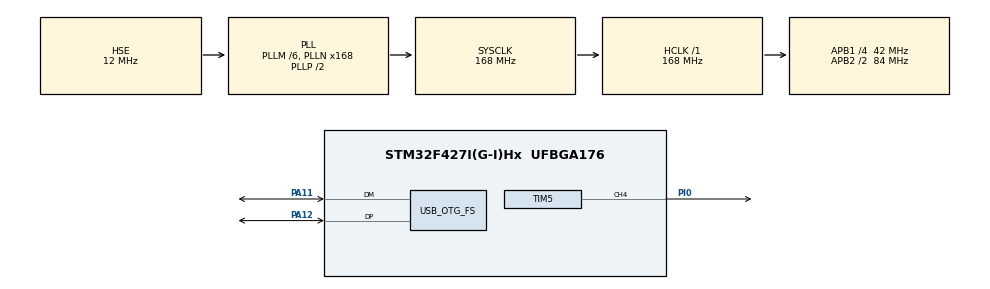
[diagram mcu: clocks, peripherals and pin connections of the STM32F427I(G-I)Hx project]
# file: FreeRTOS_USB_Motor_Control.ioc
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FREERTOS.Tasks01=defaultTask,24,128,StartDefaultTask,Default,NULL,Dynamic,NULL,NULL;ServoTask,8,128,StartTask02,Default,NULL,Dynamic,NULL,NULL
Mcu.Family=STM32F4
Mcu.Name=STM32F427I(G-I)Hx
Mcu.Package=UFBGA176
NVIC.OTG_FS_IRQn=true\:5\:0\:false\:false\:true\:true\:false\:true
NVIC.PriorityGroup=NVIC_PRIORITYGROUP_4
PA11.Mode=Device_Only
PA11.Signal=USB_OTG_FS_DM
PA12.Mode=Device_Only
PA12.Signal=USB_OTG_FS_DP
PA13.Mode=Serial_Wire
PA13.Signal=SYS_JTMS-SWDIO
PA14.Mode=Serial_Wire
PA14.Signal=SYS_JTCK-SWCLK
PH0/OSC_IN.Mode=HSE-External-Oscillator
PH0/OSC_IN.Signal=RCC_OSC_IN
PH1/OSC_OUT.Mode=HSE-External-Oscillator
PH1/OSC_OUT.Signal=RCC_OSC_OUT
PI0.Signal=S_TIM5_CH4
ProjectManager.HeapSize=0x2000
ProjectManager.StackSize=0x4000
ProjectManager.TargetToolchain=MDK-ARM V5.27
RCC.48MHZClocksFreq_Value=48000000
RCC.AHBFreq_Value=168000000
RCC.APB1CLKDivider=RCC_HCLK_DIV4
RCC.APB1Freq_Value=42000000
RCC.APB1TimFreq_Value=84000000
RCC.APB2CLKDivider=RCC_HCLK_DIV2
RCC.APB2Freq_Value=84000000
RCC.APB2TimFreq_Value=168000000
RCC.CortexFreq_Value=168000000
RCC.HCLKFreq_Value=168000000
RCC.HSE_VALUE=12000000
RCC.HSI_VALUE=16000000
RCC.LSE_VALUE=32768
RCC.PLLM=6
RCC.PLLN=168
RCC.PLLQ=7
RCC.SYSCLKFreq_VALUE=168000000
RCC.SYSCLKSource=RCC_SYSCLKSOURCE_PLLCLK
RCC.VCOOutputFreq_Value=336000000
SH.S_TIM5_CH4.0=TIM5_CH4,PWM Generation4 CH4
TIM5.Channel-PWM\ Generation4\ CH4=TIM_CHANNEL_4
TIM5.Period=19999
TIM5.Prescaler=83
TIM5.Pulse-PWM\ Generation4\ CH4=2000
USB_DEVICE.CLASS_NAME_FS=CDC
USB_DEVICE.PID_CDC_FS=22339
USB_DEVICE.VirtualMode-CDC_FS=Cdc
USB_DEVICE.VirtualModeFS=Cdc_FS
USB_OTG_FS.VirtualMode=Device_Only
VP_FREERTOS_VS_CMSIS_V2.Mode=CMSIS_V2
VP_USB_DEVICE_VS_USB_DEVICE_CDC_FS.Mode=CDC_FS
board=custom

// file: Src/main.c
/* USER CODE BEGIN Header */
/**
  ******************************************************************************
  * @file           : main.c
  * @brief          : Main program body
  ******************************************************************************
  * @attention
  *
  * <h2><center>&copy; Copyright (c) 2020 STMicroelectronics.
  * All rights reserved.</center></h2>
  *
  * This software component is licensed by ST under Ultimate Liberty license
  * SLA0044, the "License"; You may not use this file except in compliance with
  * the License. You may obtain a copy of the License at:
  *                             www.st.com/SLA0044
  *
  ******************************************************************************
  */
/* USER CODE END Header */

#include "main.h"
#include "cmsis_os.h"
#include "tim.h"
#include "usb_device.h"
#include "gpio.h"

void SystemClock_Config(void);
void MX_FREERTOS_Init(void);

int main(void)
{

  /* MCU Configuration--------------------------------------------------------*/

  /* Reset of all peripherals, Initializes the Flash interface and the Systick. */
  HAL_Init();

  /* Configure the system clock */
  SystemClock_Config();

  /* Initialize all configured peripherals */
  MX_GPIO_Init();
  MX_TIM5_Init();
  /* USER CODE BEGIN 2 */
	MX_USB_DEVICE_Init();

	// Start timer 5 for PWM signal generation
	HAL_TIM_Base_Start_IT(&htim5);

	// Start timer 5 channel 4 for PWM signal generation
	HAL_TIM_PWM_Start(&htim5, TIM_CHANNEL_4);

	// Let the servo stop
	// Only applies for GM6020
	__HAL_TIM_SetCompare(&htim5, TIM_CHANNEL_4, 1500);
  /* USER CODE END 2 */
  /* Init scheduler */
  osKernelInitialize();

  /* Call init function for freertos objects (in freertos.c) */
  MX_FREERTOS_Init();

  /* Start scheduler */
  osKernelStart();

  /* We should never get here as control is now taken by the scheduler */

  /* Infinite loop */
  while (1)
  {

  }
}

void SystemClock_Config(void)
{
  RCC_OscInitTypeDef RCC_OscInitStruct = {0};
  RCC_ClkInitTypeDef RCC_ClkInitStruct = {0};

  /** Configure the main internal regulator output voltage
  */
  __HAL_RCC_PWR_CLK_ENABLE();
  __HAL_PWR_VOLTAGESCALING_CONFIG(PWR_REGULATOR_VOLTAGE_SCALE1);
  /** Initializes the CPU, AHB and APB busses clocks
  */
  RCC_OscInitStruct.OscillatorType = RCC_OSCILLATORTYPE_HSE;
  RCC_OscInitStruct.HSEState = RCC_HSE_ON;
  RCC_OscInitStruct.PLL.PLLState = RCC_PLL_ON;
  RCC_OscInitStruct.PLL.PLLSource = RCC_PLLSOURCE_HSE;
  RCC_OscInitStruct.PLL.PLLM = 6;
  RCC_OscInitStruct.PLL.PLLN = 168;
  RCC_OscInitStruct.PLL.PLLP = RCC_PLLP_DIV2;
  RCC_OscInitStruct.PLL.PLLQ = 7;
  if (HAL_RCC_OscConfig(&RCC_OscInitStruct) != HAL_OK)
  {
    Error_Handler();
  }
  /** Initializes the CPU, AHB and APB busses clocks
  */
  RCC_ClkInitStruct.ClockType = RCC_CLOCKTYPE_HCLK|RCC_CLOCKTYPE_SYSCLK
                              |RCC_CLOCKTYPE_PCLK1|RCC_CLOCKTYPE_PCLK2;
  RCC_ClkInitStruct.SYSCLKSource = RCC_SYSCLKSOURCE_PLLCLK;
  RCC_ClkInitStruct.AHBCLKDivider = RCC_SYSCLK_DIV1;
  RCC_ClkInitStruct.APB1CLKDivider = RCC_HCLK_DIV4;
  RCC_ClkInitStruct.APB2CLKDivider = RCC_HCLK_DIV2;

  if (HAL_RCC_ClockConfig(&RCC_ClkInitStruct, FLASH_LATENCY_5) != HAL_OK)
  {
    Error_Handler();
  }
}

void Error_Handler(void)
{
}

/************************ (C) COPYRIGHT STMicroelectronics *****END OF FILE****/

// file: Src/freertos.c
/* USER CODE BEGIN Header */
/**
  ******************************************************************************
  * File Name          : freertos.c
  * Description        : Code for freertos applications
  ******************************************************************************
  * @attention
  *
  * <h2><center>&copy; Copyright (c) 2020 STMicroelectronics.
  * All rights reserved.</center></h2>
  *
  * This software component is licensed by ST under Ultimate Liberty license
  * SLA0044, the "License"; You may not use this file except in compliance with
  * the License. You may obtain a copy of the License at:
  *                             www.st.com/SLA0044
  *
  ******************************************************************************
  */
/* USER CODE END Header */

#include "FreeRTOS.h"
#include "task.h"
#include "main.h"
#include "cmsis_os.h"

/* USER CODE BEGIN Includes */
#include "tim.h"
/* USER CODE END Includes */

/* Definitions for defaultTask */
osThreadId_t defaultTaskHandle;
const osThreadAttr_t defaultTask_attributes = {
  .name = "defaultTask",
  .priority = (osPriority_t) osPriorityNormal,
  .stack_size = 128
};
/* Definitions for ServoTask */
osThreadId_t ServoTaskHandle;
const osThreadAttr_t ServoTask_attributes = {
  .name = "ServoTask",
  .priority = (osPriority_t) osPriorityLow,
  .stack_size = 128
};

void StartDefaultTask(void *argument);
void StartTask02(void *argument);

extern void MX_USB_DEVICE_Init(void);
void MX_FREERTOS_Init(void); /* (MISRA C 2004 rule 8.1) */

void MX_FREERTOS_Init(void) {

  /* Create the thread(s) */
  /* creation of defaultTask */
  defaultTaskHandle = osThreadNew(StartDefaultTask, NULL, &defaultTask_attributes);

  /* creation of ServoTask */
  ServoTaskHandle = osThreadNew(StartTask02, NULL, &ServoTask_attributes);

}

void StartDefaultTask(void *argument)
{
  /* init code for USB_DEVICE */
  //MX_USB_DEVICE_Init();
  /* USER CODE BEGIN StartDefaultTask */
  /* Infinite loop */
  for(;;)
  {
    osDelay(1000);
  }
  /* USER CODE END StartDefaultTask */
}

void StartTask02(void *argument)
{
  /* USER CODE BEGIN StartTask02 */
  /* Infinite loop */
  for(;;)
  {
		//__HAL_TIM_SetCompare(&htim5, TIM_CHANNEL_4, 1460);
		osDelay(500);

		//__HAL_TIM_SetCompare(&htim5, TIM_CHANNEL_4, 1540);
		osDelay(500);
  }
  /* USER CODE END StartTask02 */
}

/************************ (C) COPYRIGHT STMicroelectronics *****END OF FILE****/
